# ADuCM302x register map
Vendor: Analog Devices; Series: ADuCM302x; File version: 1p0
CPU: CM3 r0p1, little endian, no MPU, no FPU, 3 interrupt priority bits
Registers are 32-bit, read-write, reset 0x0 unless marked. A register's access mark holds for its fields unless they carry their own. Offsets are from the block's base; [hi:lo] are bit positions.

## SPI0 — Serial Peripheral Interface
Base 0x40004000
Same registers: SPI1 0x40004400, SPI2 0x40024000
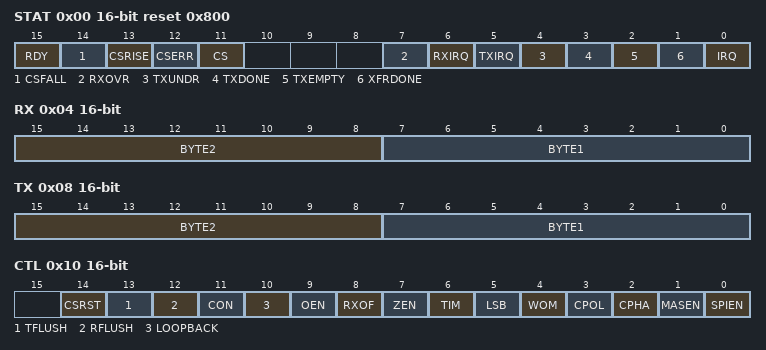
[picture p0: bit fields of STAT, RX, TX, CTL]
0x00 STAT 16-bit reset 0x800 — Status
  [15] RDY ro — Detected an Edge on Ready Indicator for Flow Control
  [14] CSFALL ro — Detected a Falling Edge on CS, in Slave CON Mode
  [13] CSRISE ro — Detected a Rising Edge on CS, in Slave CON Mode
  [12] CSERR ro — Detected a CS Error Condition in Slave Mode
  [11] CS ro — CS Status
  [7] RXOVR ro — SPI Rx FIFO Overflow
  [6] RXIRQ ro — SPI Rx IRQ
  [5] TXIRQ ro — SPI Tx IRQ
  [4] TXUNDR ro — SPI Tx FIFO Underflow
  [3] TXDONE ro — SPI Tx Done in Read Command Mode
  [2] TXEMPTY ro — SPI Tx FIFO Empty Interrupt
  [1] XFRDONE ro — SPI Transfer Completion
  [0] IRQ ro — SPI Interrupt Status
0x04 RX 16-bit — Receive
  [15:8] BYTE2 ro — 8-bit Receive Buffer, Used Only in DMA Modes
  [7:0] BYTE1 ro — 8-bit Receive Buffer
0x08 TX 16-bit — Transmit
  [15:8] BYTE2 wo range 0x00000000..0x000000FF — 8-bit Transmit Buffer, Used Only in DMA Modes
  [7:0] BYTE1 wo range 0x00000000..0x000000FF — 8-bit Transmit Buffer
0x0C DIV 16-bit — SPI Baud Rate Selection
  [5:0] VALUE range 0x00000000..0x0000003F — SPI Clock Divider
0x10 CTL 16-bit — SPI Configuration
  [14] CSRST range 0x00000000..0x00000001 — Reset Mode for CS Error Bit
  [13] TFLUSH range 0x00000000..0x00000001 — SPI Tx FIFO Flush Enable
  [12] RFLUSH range 0x00000000..0x00000001 — SPI Rx FIFO Flush Enable
  [11] CON range 0x00000000..0x00000001 — Continuous Transfer Enable
  [10] LOOPBACK range 0x00000000..0x00000001 — Loopback Enable
  [9] OEN range 0x00000000..0x00000001 — Slave MISO Output Enable
  [8] RXOF range 0x00000000..0x00000001 — Rx Overflow Overwrite Enable
  [7] ZEN range 0x00000000..0x00000001 — Transmit Zeros Enable
  [6] TIM range 0x00000000..0x00000001 — SPI Transfer and Interrupt Mode
  [5] LSB — LSB First Transfer Enable
  [4] WOM — SPI Wired-OR Mode
  [3] CPOL — Serial Clock Polarity
  [2] CPHA — Serial Clock Phase Mode
  [1] MASEN — Master Mode Enable
  [0] SPIEN — SPI Enable
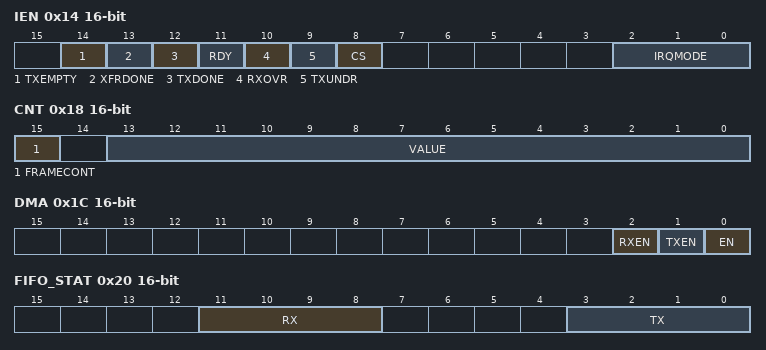
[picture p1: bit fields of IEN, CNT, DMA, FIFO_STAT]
0x14 IEN 16-bit — SPI Interrupts Enable
  [14] TXEMPTY — Tx FIFO Empty Interrupt Enable
  [13] XFRDONE — SPI Transfer Completion Interrupt Enable
  [12] TXDONE — SPI Transmit Done Interrupt Enable
  [11] RDY — Ready Signal Edge Interrupt Enable
  [10] RXOVR — Rx Overflow Interrupt Enable
  [9] TXUNDR — Tx Underflow Interrupt Enable
  [8] CS range 0x00000000..0x00000001 — Enable Interrupt on Every CS Edge in Slave CON Mode
  [2:0] IRQMODE — SPI IRQ Mode Bits
0x18 CNT 16-bit — Transfer Byte Count
  [15] FRAMECONT — Continue Frame
  [13:0] VALUE range 0x00000000..0x00003FFF — Transfer Byte Count
0x1C DMA 16-bit — SPI DMA Enable
  [2] RXEN range 0x00000000..0x00000001 — Enable Receive DMA Request
  [1] TXEN range 0x00000000..0x00000001 — Enable Transmit DMA Request
  [0] EN range 0x00000000..0x00000001 — Enable DMA for Data Transfer
0x20 FIFO_STAT 16-bit — FIFO Status
  [11:8] RX ro — SPI Rx FIFO Dtatus
  [3:0] TX ro — SPI Tx FIFO Status
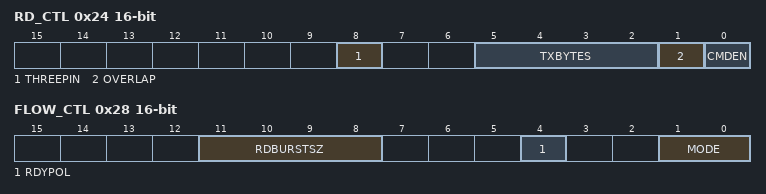
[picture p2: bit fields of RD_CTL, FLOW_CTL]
0x24 RD_CTL 16-bit — Read Control
  [8] THREEPIN — Three Pin SPI Mode
  [5:2] TXBYTES range 0x00000000..0x0000000F — Transmit Byte Count - 1 (Read Command)
  [1] OVERLAP — Tx/Rx Overlap Mode
  [0] CMDEN — Read Command Enable
0x28 FLOW_CTL 16-bit — Flow Control
  [11:8] RDBURSTSZ range 0x00000000..0x0000000F — Read Data Burst Size - 1
  [4] RDYPOL — Polarity of RDY/MISO Line
  [1:0] MODE — Flow Control Mode
0x2C WAIT_TMR 16-bit — Wait Timer for Flow Control
  [15:0] VALUE range 0x00000000..0x0000FFFF — Wait Timer
0x30 CS_CTL 16-bit reset 0x1 — Chip Select Control for Multi-slave Connections
  [3:0] SEL range 0x00000000..0x0000000F — Chip Select Control
0x34 CS_OVERRIDE 16-bit — Chip Select Override
  [1:0] CTL — CS Override Control
